# MAILBOX register map
Vendor: Texas Instruments
Peripheral module from a debugger description file (folder am437x).
Registers are 32-bit, access per field, no defined reset value unless marked. A register's access mark holds for its fields unless they carry their own. Offsets are as the file gives them; lines under a group give offsets from that group; [hi:lo] are bit positions; {n}, {i} and the like mark numbered series; 'fields as' and 'values as' point back to an identical list; <NAME> marks a mode.

## MAILBOX
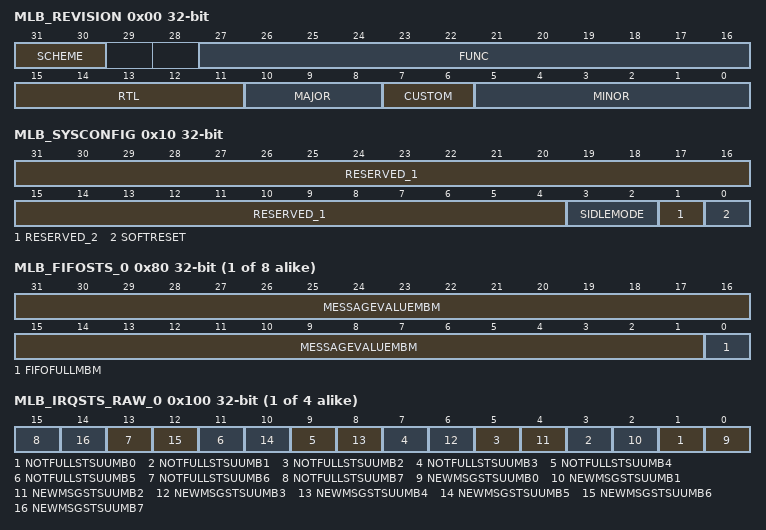
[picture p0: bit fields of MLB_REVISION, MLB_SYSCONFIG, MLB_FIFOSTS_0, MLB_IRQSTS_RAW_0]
0x00 MLB_REVISION ro — This register contains the IP revision code
  [31:30] SCHEME — Not defined yet
  [27:16] FUNC — Not defined yet
  [15:11] RTL — Not defined yet
  [10:8] MAJOR — IP-Major Revision
  [7:6] CUSTOM — Not Defined Yet
  [5:0] MINOR — IP-Minor Revision
0x10 MLB_SYSCONFIG rw — This register controls the various parameters of the OCP interface
  [31:4] RESERVED_1 — Write 0's for future compatibility Reads returns 0
  [3:2] SIDLEMODE
  [1] RESERVED_2 — Write 0's for future compatibility Read returns 0
  [0] SOFTRESET — Software reset. [[br]]This bit is automatically reset by the hardware. [[br]]During reads, it always return 0
    1=en_2_0x1 (The module is reset); 0=en_1_0x0 (Normal mode)
{0x40+4i} MLB_MESSAGE_{i} rw (i=0..7) — The message register stores the next to be read message of the mailbox. Reads remove the message from the FIFO queue
  [31:0] MESSAGEVALUEMBM — Message in Mailbox. [[br]]The message register stores the next to be read message of the mailbox. [[br]]Reads remove the message from the FIFO queue.
{0x80+4i} MLB_FIFOSTS_{i} (i=0..7) — The message register stores the next to be read message of the mailbox. Reads remove the message from the FIFO queue
  [31:1] MESSAGEVALUEMBM rw — Message in Mailbox. [[br]]The message register stores the next to be read message of the mailbox. [[br]]Reads remove the message from the FIFO queue.
  [0] FIFOFULLMBM ro — Full flag for Mailbox
    1=en_2_0x1 (Mailbox FIFO is full); 0=en_1_0x0 (Mailbox FIFO is not full)
{0xC0+4i} MLB_MSGSTS_{i} ro (i=0..7) — The message status register has the status of the messages in the mailbox
  [2:0] NBOFMSGMBM — Number of unread messages in Mailbox. [[br]]Limited to four messages per mailbox.
{0x100+0x10*i} MLB_IRQSTS_RAW_{i} (i=0..3) — The interrupt status register has the status for each event that may be responsible for the generation of an interrupt to the corresponding user - write 1 to a given bit resets this bit. This register is mainly used for debug purpose.
  [all] fields
    1=en_2_0x1 (Set the event (for debug)); 0=en_1_0x0 (No action)
  [2n+1] NOTFULLSTSUUMB{n} rw (n=0..7) — Not Full Status bit for User u, Mailbox {n}
  [2n] NEWMSGSTSUUMB{n} rw (n=0..7) — New Message Status bit for User u, Mailbox {n}
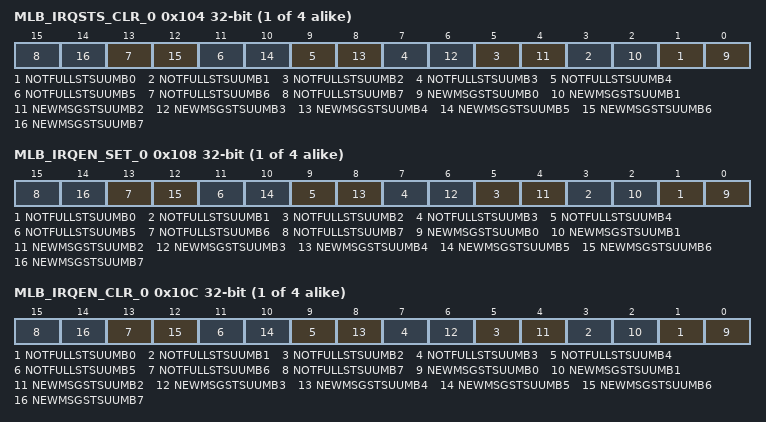
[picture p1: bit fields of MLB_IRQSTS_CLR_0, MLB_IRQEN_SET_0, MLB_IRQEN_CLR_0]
{0x104+0x10*i} MLB_IRQSTS_CLR_{i} (i=0..3) — The interrupt status register has the status combined with irq-enable for each event that may be responsible for the generation of an interrupt to the corresponding user - write 1 to a given bit resets this bit.
  fields as MLB_IRQSTS_RAW_0
{0x108+0x10*i} MLB_IRQEN_SET_{i} (i=0..3) — The interrupt enable register enables to unmask the module internal source of interrupt to the corresponding user. This register is write 1 to set.
  fields as MLB_IRQSTS_RAW_0
{0x10C+0x10*i} MLB_IRQEN_CLR_{i} (i=0..3) — The interrupt enable register enables to mask the module internal source of interrupt to the corresponding user. This register is write 1 to clear.
  fields as MLB_IRQSTS_RAW_0
